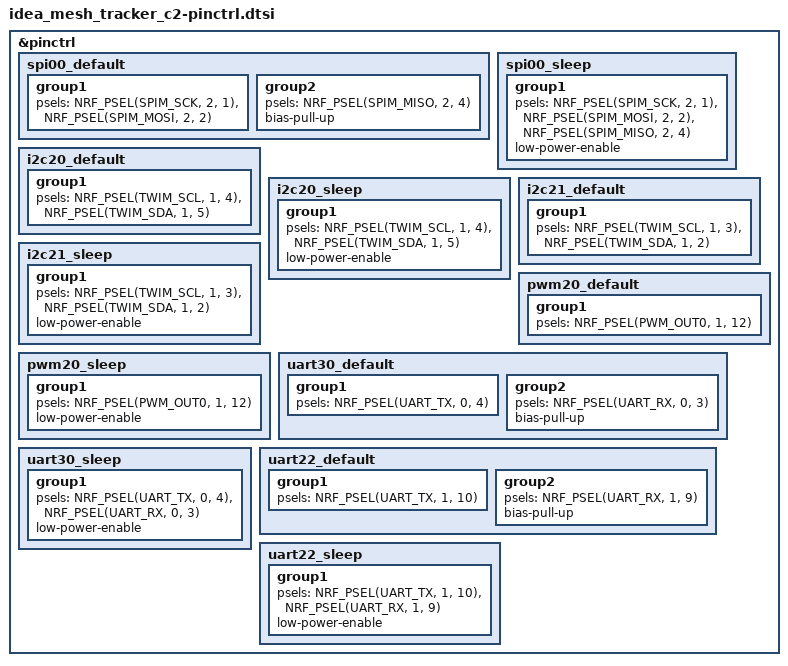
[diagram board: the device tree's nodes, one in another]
/*
 * SPDX-License-Identifier: Apache-2.0
 */

&pinctrl {

	/omit-if-no-ref/ spi00_default: spi00_default {
		group1 {
			psels = <NRF_PSEL(SPIM_SCK, 2, 1)>,
				<NRF_PSEL(SPIM_MOSI, 2, 2)>;
		};

		group2 {
			psels = <NRF_PSEL(SPIM_MISO, 2, 4)>;
			bias-pull-up;
		};
	};

	/omit-if-no-ref/ spi00_sleep: spi00_sleep {
		group1 {
			psels = <NRF_PSEL(SPIM_SCK, 2, 1)>,
				<NRF_PSEL(SPIM_MOSI, 2, 2)>,
				<NRF_PSEL(SPIM_MISO, 2, 4)>;
			low-power-enable;
		};
	};

	/omit-if-no-ref/ i2c20_default: i2c20_default {
		group1 {
			psels = <NRF_PSEL(TWIM_SCL, 1, 4)>,
				<NRF_PSEL(TWIM_SDA, 1, 5)>;
		};
	};

	/omit-if-no-ref/ i2c20_sleep: i2c20_sleep {
		group1 {
			psels = <NRF_PSEL(TWIM_SCL, 1, 4)>,
				<NRF_PSEL(TWIM_SDA, 1, 5)>;
			low-power-enable;
		};
	};

	/omit-if-no-ref/ i2c21_default: i2c21_default {
		group1 {
			psels = <NRF_PSEL(TWIM_SCL, 1, 3)>,
				<NRF_PSEL(TWIM_SDA, 1, 2)>;
		};
	};

	/omit-if-no-ref/ i2c21_sleep: i2c21_sleep {
		group1 {
			psels = <NRF_PSEL(TWIM_SCL, 1, 3)>,
				<NRF_PSEL(TWIM_SDA, 1, 2)>;
			low-power-enable;
		};
	};

	/omit-if-no-ref/ pwm20_default: pwm20_default {
		group1 {
			psels = <NRF_PSEL(PWM_OUT0, 1, 12)>;
		};
	};

	/omit-if-no-ref/ pwm20_sleep: pwm20_sleep {
		group1 {
			psels = <NRF_PSEL(PWM_OUT0, 1, 12)>;
			low-power-enable;
		};
	};

	/omit-if-no-ref/ uart30_default: uart30_default {
		group1 {
			psels = <NRF_PSEL(UART_TX, 0, 4)>;
		};

		group2 {
			psels = <NRF_PSEL(UART_RX, 0, 3)>;
			bias-pull-up;
		};
	};

	/omit-if-no-ref/ uart30_sleep: uart30_sleep {
		group1 {
			psels = <NRF_PSEL(UART_TX, 0, 4)>,
				<NRF_PSEL(UART_RX, 0, 3)>;
			low-power-enable;
		};
	};

	/omit-if-no-ref/ uart22_default: uart22_default {
		group1 {
			psels = <NRF_PSEL(UART_TX, 1, 10)>;
		};

		group2 {
			psels = <NRF_PSEL(UART_RX, 1, 9)>;
			bias-pull-up;
		};
	};

	/omit-if-no-ref/ uart22_sleep: uart22_sleep {
		group1 {
			psels = <NRF_PSEL(UART_TX, 1, 10)>,
				<NRF_PSEL(UART_RX, 1, 9)>;
			low-power-enable;
		};
	};

};
